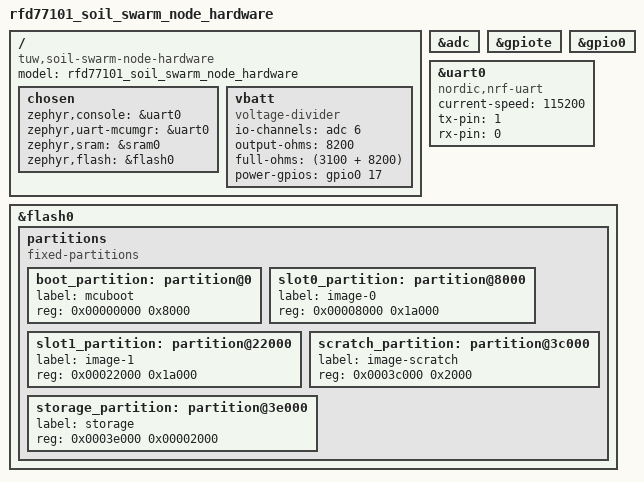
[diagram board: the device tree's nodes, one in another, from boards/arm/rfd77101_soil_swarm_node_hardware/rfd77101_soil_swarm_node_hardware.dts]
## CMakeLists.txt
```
cmake_minimum_required(VERSION 3.8.2)

set(BOARD_ROOT ${CMAKE_CURRENT_LIST_DIR})
set(BOARD rfd77101_soil_swarm_node_hardware)

include($ENV{ZEPHYR_BASE}/cmake/app/boilerplate.cmake NO_POLICY_SCOPE)
project(peripheral)

target_sources(app PRIVATE
  src/main.c
  src/node.c
  src/util.c
  
  src/battery.c
  src/moisture.c
  src/onewire.c
  src/ds18b20.c
  
  src/ass.c
  src/bas.c
  src/cts.c
  src/ess.c
  
  # src/sys_fatal_error_handler.c
)
```

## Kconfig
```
# Copyright (c) 2020 Christian Hirsch
# SPDX-License-Identifier: Apache-2.0

config MEASUREMENTS_SIZE
        int "Number of measurements stored in RAM"
        default 480
        range 0 4094

config SENSE_INTERVAL
        int "Number of measurements stored in RAM"
        default 10
        range 0 4094

source "Kconfig.zephyr"
```

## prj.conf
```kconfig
prj.release.conf
```

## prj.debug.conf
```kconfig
CONFIG_SYSTEM_WORKQUEUE_STACK_SIZE=2048
CONFIG_HEAP_MEM_POOL_SIZE=1024

CONFIG_LOG=y
CONFIG_LOG_BACKEND_UART=y
CONFIG_LOG_DEFAULT_LEVEL=4
CONFIG_LOG_MAX_LEVEL=4

# DEBUGGING
CONFIG_DEBUG=n
CONFIG_BT_DEBUG_LOG=y

# REBOOT
CONFIG_REBOOT=y

# DEVICES
CONFIG_GPIO=y

# BLUETOOTH
CONFIG_BT=y
CONFIG_BT_PERIPHERAL=y
CONFIG_BT_DEVICE_NAME="soil-swarm-node"
CONFIG_BT_CTLR_TX_PWR_PLUS_4=y

CONFIG_ADC=y

CONFIG_PWM=y
```

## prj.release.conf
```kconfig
CONFIG_SYSTEM_WORKQUEUE_STACK_SIZE=2048
CONFIG_HEAP_MEM_POOL_SIZE=1024

# one measurement per 15 min -> 96 / day
CONFIG_SENSE_INTERVAL=900
CONFIG_MEASUREMENTS_SIZE=900

# POWER SAVING
CONFIG_DEBUG=n
CONFIG_SERIAL=n
CONFIG_UART_NRFX=n
CONFIG_BT_DEBUG_LOG=n

# Optimization
CONFIG_SPEED_OPTIMIZATIONS=y

CONFIG_LOG=n
CONFIG_LOG_BACKEND_UART=n

CONFIG_CONSOLE=n
CONFIG_UART_CONSOLE=n

# GENERAL
CONFIG_REBOOT=y

# DEVICES
CONFIG_ADC=y
CONFIG_GPIO=y
CONFIG_PWM=y

# BLUETOOTH
CONFIG_BT=y
CONFIG_BT_PERIPHERAL=y
CONFIG_BT_DEVICE_NAME="soil-swarm-node"
CONFIG_BT_CTLR_TX_PWR_PLUS_4=y

CONFIG_BT_RX_BUF_LEN=130
CONFIG_BT_ATT_TX_MAX=5
CONFIG_BT_ATT_PREPARE_COUNT=2
CONFIG_BT_L2CAP_TX_BUF_COUNT=5
CONFIG_BT_L2CAP_TX_MTU=119
CONFIG_BT_L2CAP_DYNAMIC_CHANNEL=y
CONFIG_BT_CTLR_RX_BUFFERS=2
CONFIG_BT_CTLR_TX_BUFFERS=5
CONFIG_BT_CTLR_TX_BUFFER_SIZE=123
CONFIG_BT_CTLR_DATA_LENGTH_MAX=123
CONFIG_BT_CTLR_ADVANCED_FEATURES=y
CONFIG_BT_CTLR_XTAL_THRESHOLD=500000
```

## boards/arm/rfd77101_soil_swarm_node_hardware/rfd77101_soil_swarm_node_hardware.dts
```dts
/*
 * Copyright (c) 2020 Christian Hirsch
 *
 * SPDX-License-Identifier: Apache-2.0
 */

/dts-v1/;
#include <nordic/nrf51822_qfac.dtsi>

/ {
	model = "rfd77101_soil_swarm_node_hardware";
	compatible = "tuw,soil-swarm-node-hardware";

	chosen {
		zephyr,console = &uart0;
		zephyr,uart-mcumgr = &uart0;
		zephyr,sram = &sram0;
		zephyr,flash = &flash0;
	};
    
	vbatt {
		compatible = "voltage-divider";
		io-channels = <&adc 6>;	/* AIN6 P0.05 */
		output-ohms = <8200>;
		full-ohms = <(3100 + 8200)>;
		power-gpios = <&gpio0 17 0>;
	};
};

&adc {
	status = "okay";
};

&gpiote {
	status = "okay";
};

&gpio0 {
	status = "okay";
};

&uart0 {
		compatible = "nordic,nrf-uart";
        status = "okay";
        current-speed = <115200>;
        tx-pin = <1>;
        rx-pin = <0>;
};

&flash0 {
        /*
         * For more information, see:
         * http://docs.zephyrproject.org/latest/devices/dts/flash_partitions.html
         */
        partitions {
                compatible = "fixed-partitions";
                #address-cells = <1>;
                #size-cells = <1>;

                boot_partition: partition@0 {
                        label = "mcuboot";
                        reg = <0x00000000 0x8000>;
                };
                slot0_partition: partition@8000 {
                        label = "image-0";
                        reg = <0x00008000 0x1a000>;
                };
                slot1_partition: partition@22000 {
                        label = "image-1";
                        reg = <0x00022000 0x1a000>;
                };
                scratch_partition: partition@3c000 {
                        label = "image-scratch";
                        reg = <0x0003c000 0x2000>;
                };
                storage_partition: partition@3e000 {
                        label = "storage";
                        reg = <0x0003e000 0x00002000>;
                };
        };
};
```

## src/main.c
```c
/* main.c - Application main for soil-swarm-node */

#include <zephyr.h>
#include <zephyr/types.h>
#include <sys/byteorder.h>
#include <logging/log.h>
#include <settings/settings.h>
#include <device.h>
#include <drivers/gpio.h>
#include <soc.h>

#include <stddef.h>
#include <string.h>
#include <errno.h>

#include <bluetooth/bluetooth.h>
#include <bluetooth/hci.h>
#include <bluetooth/conn.h>
#include <bluetooth/uuid.h>
#include <bluetooth/gatt.h>

#include "node.h"

#include "config.h"

#define BT_LE_ADV_CONN_NAME_ID BT_LE_ADV_PARAM(BT_LE_ADV_OPT_CONNECTABLE | \
		BT_LE_ADV_OPT_USE_NAME | BT_LE_ADV_OPT_USE_IDENTITY, \
		BT_GAP_ADV_SLOW_INT_MIN, \
		BT_GAP_ADV_SLOW_INT_MAX, NULL)

// BT_GAP_ADV_SLOW_INT_MIN = 0x0640 ^= 1s
// BT_GAP_ADV_SLOW_INT_MAX = 0x0780 ^= 1.2s
#define BT_LE_ADV_NCONN_NAME_ID BT_LE_ADV_PARAM(BT_LE_ADV_OPT_USE_NAME | \
		BT_LE_ADV_OPT_USE_IDENTITY, \
		BT_GAP_ADV_SLOW_INT_MIN, \
		BT_GAP_ADV_SLOW_INT_MAX, NULL)

LOG_MODULE_REGISTER(main);

K_THREAD_STACK_DEFINE(disconnect_timeout_stack, 32);
struct k_thread disconnect_timeout_data;
k_tid_t disconnect_timeout_tid;

void disconnect_timeout(void *, void *, void *);

extern volatile struct time_sync remote_ts;

static bool is_client_connected  = false;
bool is_sync_enabled = false;
struct bt_conn *client_connected = 0;
u32_t time_connected = 0;

struct bt_conn *default_conn;

u16_t num_connected = 0;

struct bt_le_adv_param *adv_params = BT_LE_ADV_CONN_NAME_ID;

static const struct bt_data ad[] = {
		BT_DATA_BYTES(BT_DATA_FLAGS, BT_LE_AD_NO_BREDR),
		BT_DATA_BYTES(BT_DATA_UUID16_ALL, 0xaa, 0xfe),
		BT_DATA_BYTES(BT_DATA_SVC_DATA16,
				0xaa, 0xfe, /* Eddystone UUID */
				0x10, /* Eddystone-URL frame type */
				0x04, /* Calibrated Tx power at 0m */
				0x00, /* URL Scheme Prefix http://www. */
				//'a','f','a','r','c','l','o','u','d','.','e','u','/')
				'a','f','a','r','c','l','o','u','d','.','a','t','/')
};

void start_advertising() {
	bt_le_adv_start(BT_LE_ADV_CONN_NAME_ID, ad, ARRAY_SIZE(ad), NULL, 0);
	return;
	int err = 0, err_cnt = 0;
	do {
		err = bt_le_adv_start(adv_params, ad, ARRAY_SIZE(ad), NULL, 0);
		if(err == 0 || err_cnt > 3)
			break;
		err_cnt++;
		k_sleep(K_MSEC(15));
	} while(err);

	if (err) {
		LOG_ERR("Advertising failed to start (err %d)", err);
		return;
	}
	LOG_INF("Advertising successfully started");
}

static void connected(struct bt_conn *conn, u8_t err)
{
	if (err) {
		LOG_INF("Connection failed (err %u)\n", err);
		return;
	}

	client_connected = conn;
	is_client_connected = true;

	disconnect_timeout_tid = k_thread_create(&disconnect_timeout_data,
			disconnect_timeout_stack,
			K_THREAD_STACK_SIZEOF(disconnect_timeout_stack),
			disconnect_timeout,
			NULL, NULL, NULL, 1, 0, K_SECONDS(300));
	num_connected++;

	LOG_INF("Connected (%u times)", num_connected);
}

static void disconnected(struct bt_conn *conn, u8_t reason)
{
	LOG_INF("Disconnected (reason %u)\n", reason);
	is_client_connected = false;

	if (disconnect_timeout_tid)
	{
		k_wakeup(disconnect_timeout_tid);
	}
}

static void bt_ready(int err)
{
	if (err) {
		LOG_ERR("Bluetooth init failed (err %d)", err);
		return;
	}
	LOG_INF("Bluetooth initialized");

	if (IS_ENABLED(CONFIG_SETTINGS)) {
		settings_load();
	}

	start_advertising();
}

static struct bt_conn_cb conn_callbacks = {
	.connected = connected,
	.disconnected = disconnected,
};

void disconnect_timeout(void *v1, void *v2, void *v3)
{
	/* if connection is still up after 15min, (auto-)disconnect */
	if (is_client_connected == true)
	{
		bt_conn_disconnect(client_connected, BT_HCI_ERR_REMOTE_USER_TERM_CONN);
	}

	disconnect_timeout_tid = 0;
}

void main(void)
{
	int err = 0;

	err = bt_enable(bt_ready);
	if (err != 0) {
		LOG_ERR("Bluetooth init failed (err %d)", err);
		return;
	}
	bt_conn_cb_register(&conn_callbacks);

	while (1) {
		k_sleep(K_FOREVER);
	}
}
```

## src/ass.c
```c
#include "ass.h"

#include "uuid.h"
#include "node.h"

#include <logging/log.h>

#include <bluetooth/gatt.h>
#include <bluetooth/conn.h>

static u8_t *data_buf = NULL;

static u8_t indicate_enabled = 0;
static u16_t mtu_size = 0;

static size_t buffer_size = 0;
static size_t mtu_buffer_size = 0;

struct bt_gatt_indicate_params i_params;

extern struct bt_conn *client_connected;

LOG_MODULE_REGISTER(ASS);

static void sync_ccc_cfg_changed(const struct bt_gatt_attr *attr,
			u16_t value);
static void ass_indicate(void);

/* ASS Declaration */
BT_GATT_SERVICE_DEFINE(ass_svc,
	BT_GATT_PRIMARY_SERVICE(BT_UUID_ASS),

	BT_GATT_CHARACTERISTIC(BT_UUID_ASS_GSC,
			       BT_GATT_CHRC_READ | BT_GATT_CHRC_INDICATE,
			       BT_GATT_PERM_READ, NULL, NULL, NULL),

	BT_GATT_CCC(sync_ccc_cfg_changed, BT_GATT_PERM_READ | BT_GATT_PERM_WRITE),

	BT_GATT_DESCRIPTOR(BT_UUID_ASS_UTD, BT_GATT_PERM_NONE, NULL, NULL, 0),
	BT_GATT_DESCRIPTOR(BT_UUID_ASS_BVD, BT_GATT_PERM_NONE, NULL, NULL, 0),
	BT_GATT_DESCRIPTOR(BT_UUID_ASS_STD, BT_GATT_PERM_NONE, NULL, NULL, 0),
	BT_GATT_DESCRIPTOR(BT_UUID_ASS_RSHD, BT_GATT_PERM_NONE, NULL, NULL, 0),
);

static void indicate_cb(struct bt_conn *conn, const struct bt_gatt_attr *attr,
			u8_t err)
{
	LOG_INF("Indication %s\n", err != 0U ? "fail" : "success");
	node_buf_get_finish(mtu_buffer_size);
	ass_indicate();
}

static void sync_ccc_cfg_changed(const struct bt_gatt_attr *attr,
				 u16_t value)
{
	indicate_enabled = (value == BT_GATT_CCC_INDICATE) ? 1 : 0;

	LOG_INF("sync_ccc_cfg_changed to %u", value);

	if (indicate_enabled)
	{
		mtu_size = bt_gatt_get_mtu(client_connected);
		LOG_INF("mtu size = %u", mtu_size);

		data_buf = (u8_t *)k_malloc(mtu_size);

		if(data_buf == 0)
		{
			LOG_ERR("error allocating %u bytes of memory", mtu_size);
			return;
		}

		i_params.attr = &ass_svc.attrs[2];
		i_params.data = data_buf;
		i_params.func = indicate_cb;

		buffer_size = node_buf_get_elem_size();
		mtu_buffer_size = (mtu_size - 4) / buffer_size;

		ass_indicate();
	}
	else {
		k_free(data_buf);
		data_buf = 0;
	}
}

static void ass_indicate(void)
{
	if(!indicate_enabled)
		return;

	LOG_INF("send indication");

	data_buf[0] = (u8_t) node_buf_cpy_data((void *)&data_buf[1],
			mtu_buffer_size);

	i_params.len  = sizeof(data_buf[0]) + data_buf[0] * buffer_size;
	if (data_buf[0] == 0) {
		i_params.func = NULL;
	}

	int err = bt_gatt_indicate(NULL, &i_params);
	if (err != 0) {
		LOG_ERR("error sending indication: %i", err);
	}
}
```

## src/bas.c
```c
#include <zephyr.h>
#include <zephyr/types.h>

#include <bluetooth/bluetooth.h>
#include <bluetooth/conn.h>
#include <bluetooth/uuid.h>
#include <bluetooth/gatt.h>

#include "battery.h"

static ssize_t read_blvl(struct bt_conn *conn, const struct bt_gatt_attr *attr,
		void *buf, u16_t len, u16_t offset)
{
	u16_t value = (u16_t) battery_sample();// battery_level_pptt(battery_sample());

	return bt_gatt_attr_read(conn, attr, buf, len, offset, &value,
			sizeof(value));
}

/* Battery Service Declaration */
BT_GATT_SERVICE_DEFINE(bas_svc,
	BT_GATT_PRIMARY_SERVICE(BT_UUID_BAS),
	BT_GATT_CHARACTERISTIC(BT_UUID_BAS_BATTERY_LEVEL,
			BT_GATT_CHRC_READ | BT_GATT_CHRC_NOTIFY,
			BT_GATT_PERM_READ, read_blvl, NULL, NULL),
	BT_GATT_CCC(NULL, BT_GATT_PERM_NONE)
);
```

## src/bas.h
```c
/** @file
 *  @brief BAS Service sample
 */

/*
 * Copyright (c) 2016 Intel Corporation
 *
 * SPDX-License-Identifier: Apache-2.0
 */

#ifdef __cplusplus
extern "C" {
#endif

int  bas_notify(u16_t _battery_lvl);

#ifdef __cplusplus
}
#endif
```

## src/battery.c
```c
//#include "battery.h"

//#include "settings.h"
#include <device.h>
#include <drivers/gpio.h>

#include <drivers/adc.h>
#include <hal/nrf_adc.h>

#define BATTERY_EN_PIN 17

struct device *battery_en;

#define BUFFER_SIZE 1
static int32_t m_sample_buffer[BUFFER_SIZE];

struct device *adc_dev;

static const struct adc_channel_cfg adc_cfg = {
    .gain             = ADC_GAIN_1_3,
    .reference        = ADC_REF_VDD_1_3,
    .acquisition_time = ADC_ACQ_TIME_DEFAULT,
//    .channel_id       = ADC_1ST_CHANNEL_ID,
//    .channel_id       = BATTERY_SENSE_PIN,
    .input_positive   = NRF_ADC_CONFIG_INPUT_6,
};

struct adc_sequence adc_sequence = {
//    .channels    = BIT(ADC_1ST_CHANNEL_ID),
    .buffer      = m_sample_buffer,
    .buffer_size = sizeof(m_sample_buffer),
    .resolution  = 10,
};

int battery_init(struct device *a_dev) {
    battery_en = device_get_binding(DT_LABEL(DT_ALIAS(gpio_0)));

    gpio_pin_configure(battery_en, BATTERY_EN_PIN, GPIO_OUTPUT);
    gpio_pin_set(battery_en, BATTERY_EN_PIN, 0);

	adc_dev = device_get_binding(DT_LABEL(DT_ALIAS(adc_0)));

    if(adc_dev == 0)
        return -1;

    return adc_channel_setup(adc_dev, &adc_cfg);
}

int16_t battery_sample() {
	int err = 0;

    if(adc_channel_setup(adc_dev, &adc_cfg) != 0)
        return -1;
    adc_sequence.channels = BIT(adc_cfg.channel_id);

    gpio_pin_set(battery_en, BATTERY_EN_PIN, 1);
    err = adc_read(adc_dev, &adc_sequence);
    gpio_pin_set(battery_en, BATTERY_EN_PIN, 0);

    err = adc_raw_to_millivolts(1000, adc_cfg.gain, adc_sequence.resolution, &m_sample_buffer[0]);
    if (err == 0) {
    	m_sample_buffer[0] *= (82+31);
    	m_sample_buffer[0] /= (82);
    }

    if(err < 0)
        return -EIO;

    return m_sample_buffer[0];
}
```

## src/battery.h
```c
/*
 * Copyright (c) 2018-2019 Peter Bigot Consulting, LLC
 *
 * SPDX-License-Identifier: Apache-2.0
 */

#ifndef APPLICATION_BATTERY_H_
#define APPLICATION_BATTERY_H_

/** Enable or disable measurement of the battery voltage.
 *
 * @param enable true to enable, false to disable
 *
 * @return zero on success, or a negative error code.
 */
int battery_measure_enable(bool enable);

/** Measure the battery voltage.
 *
 * @return the battery voltage in millivolts, or a negative error
 * code.
 */
s16_t battery_sample(void);

/** A point in a battery discharge curve sequence.
 *
 * A discharge curve is defined as a sequence of these points, where
 * the first point has #lvl_pptt set to 10000 and the last point has
 * #lvl_pptt set to zero.  Both #lvl_pptt and #lvl_mV should be
 * monotonic decreasing within the sequence.
 */
struct battery_level_point {
	/** Remaining life at #lvl_mV. */
	u16_t lvl_pptt;

	/** Battery voltage at #lvl_pptt remaining life. */
	u16_t lvl_mV;
};

/** Calculate the estimated battery level based on a measured voltage.
 *
 * @param batt_mV a measured battery voltage level.
 *
 * @param curve the discharge curve for the type of battery installed
 * on the system.
 *
 * @return the estimated remaining capacity in parts per ten
 * thousand.
 */
u16_t battery_level_pptt(unsigned int batt_mV);

void battery_charge_enable(void);
void battery_charge_disable(void);
u8_t battery_charge_is_enabled(void);

#endif /* APPLICATION_BATTERY_H_ */
```

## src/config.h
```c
#define SENSE_INTERVAL CONFIG_SENSE_INTERVAL
#define MEASUREMENTS_SIZE CONFIG_MEASUREMENTS_SIZE

#define LED_PORT "GPIO_0"
#define LED_P    6
#define LED_N    4

#define BATTERY_EN_PORT "GPIO_0"
#define BATTERY_EN_PIN  17

#define ONEWIRE_PORT "GPIO_0"
#define ONEWIRE_PIN  14

#define DS18B20_EN_PORT "GPIO_0"
#define DS18B20_EN_PIN  13

#define SENSE_EN_PORT "GPIO_0"
#define SENSE_EN_PIN  7

#define SENSE_EXCITATION_PORT "GPIO_0"
#define SENSE_EXCITATION_PIN  10

#define SENSE_LOW_PIN   NRF_ADC_CONFIG_INPUT_3   //P0.02/AIN3
#define SENSE_HIGH_PIN  NRF_ADC_CONFIG_INPUT_4   //P0.03/AIN4

#define ADC_RESOLUTION          10
#define ADC_GAIN                ADC_GAIN_1_3
#define ADC_REFERENCE           ADC_REF_INTERNAL
#define ADC_ACQUISITION_TIME    ADC_ACQ_TIME_DEFAULT
#define BATTERY_SENSE_PIN       ADC_CONFIG_PSEL_AnalogInput6  // P0.05/GPIO5/ANALOG6
```

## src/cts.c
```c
#include <zephyr.h>
#include <zephyr/types.h>
#include <stddef.h>
#include <string.h>
#include <time.h>
#include <errno.h>

#include <sys/byteorder.h>

#include <bluetooth/bluetooth.h>
#include <bluetooth/hci.h>
#include <bluetooth/conn.h>
#include <bluetooth/uuid.h>
#include <bluetooth/gatt.h>

#include "cts.h"
#include "node.h"
#include "config.h"

#include <drivers/counter.h>

static  u8_t cts_exact_time_256[10];
static  u8_t cts_update;

s64_t cts_uptime_synced_ms = 0;
u32_t cts_uptime_synced_s  = 0;
u32_t cts_ref_unix_sec     = 0;

static u8_t counting = 0;

static ssize_t read_cts(struct bt_conn *conn, const struct bt_gatt_attr *attr,
		void *buf, u16_t len, u16_t offset);
static ssize_t write_cts(struct bt_conn *conn, const struct bt_gatt_attr *attr,
		const void *buf, u16_t len, u16_t offset,
		u8_t flags);

/* Battery Service Declaration */
BT_GATT_SERVICE_DEFINE(cts_svc,
		BT_GATT_PRIMARY_SERVICE(BT_UUID_CTS),
		BT_GATT_CHARACTERISTIC(BT_UUID_CTS_CURRENT_TIME,
				BT_GATT_CHRC_READ | BT_GATT_CHRC_WRITE,
				BT_GATT_PERM_READ | BT_GATT_PERM_WRITE,
				read_cts, write_cts, cts_exact_time_256),
				BT_GATT_CCC(NULL, BT_GATT_PERM_NONE),
);

/* no leap seconds! */
static u32_t exact_time_256_to_unix_sec(u8_t *ct)
{
	u32_t year = (u32_t)sys_le16_to_cpu(*(u16_t *)ct);

	u32_t time_sec = (year - 1) / 4;
	time_sec   = (time_sec - 492) * 24 * 60 * 60;		// leap year days
	time_sec  += (year - 1970) * 365 * 24 * 60 * 60;	//without leap year

	for(u8_t i=1; i<ct[2]; i++)
	{
		switch(i) {
		case 2:
			time_sec += 28 * 24 * 60 * 60;
			if(year % 4 == 0)
			{
				time_sec += 24 * 60 * 60;
			}
			break;
		case 4:
		case 6:
		case 9:
		case 11:
			time_sec += 30 * 24 * 60 * 60;
			break;
		default:
			time_sec += 31 * 24 * 60 * 60;
			break;
		}
	}

	time_sec += (ct[3]-1) * 24 * 60 * 60;	// day of month
	time_sec += (ct[4]) * 60 * 60;			// hours
	time_sec += (ct[5]) * 60;				// minutes
	time_sec += (ct[6]);					// seconds

	return time_sec;
}

static void unix_sec_to_exact_time_256(u32_t unix_sec, u8_t *et256)
{
	u32_t tmp = 0;

	/* seconds */
	et256[6] =  unix_sec % 60;

	/* minutes */
	et256[5] = (unix_sec / 60) % 60;

	/* hours */
	et256[4] = (unix_sec / 3600) % 24;

	/* year */
	tmp  = (unix_sec / 3600 / 24) * 100;
	tmp /= 36525;
	tmp += 1970;
	memcpy(&et256[0], &tmp, sizeof(tmp));

	/* day of month */
	tmp  = (u32_t) *(u16_t *)et256 - 1970;
	tmp *= 36525;
	tmp += 50;
	tmp /= 100;
	tmp  = (unix_sec / 3600 / 24) - tmp + 1;

	for(et256[2] = 1; et256[2] < 13 ; et256[2]++)
	{
		u8_t days;
		switch(et256[2])
		{
		case 2:
			days = 28;
			break;
		case 4:
		case 6:
		case 9:
		case 11:
			days = 30;
			break;
		default:
			days = 31;
			break;
		}
		if (tmp < days)
			break;
		tmp -= days;
	}

	et256[3] = (u8_t) tmp;
	if (et256[2] < 3 && (*(u16_t *)et256 - 1970) % 4 == 2) {
		et256[3]++;
	}
}

static ssize_t read_cts(struct bt_conn *conn, const struct bt_gatt_attr *attr,
		void *buf, u16_t len, u16_t offset)
{
	u8_t et256[10] = { 0 };

	s64_t now  = (k_uptime_get() - cts_uptime_synced_ms) / 1000;

	u32_t now32 = (u32_t) now;
	now32 += cts_ref_unix_sec;

	unix_sec_to_exact_time_256(now32, et256);

	int err = bt_gatt_attr_read(conn, attr, buf, len, offset, et256,
			sizeof(et256));

	return err;
}

static ssize_t write_cts(struct bt_conn *conn, const struct bt_gatt_attr *attr,
		const void *buf, u16_t len, u16_t offset,
		u8_t flags)
{
	s64_t now = k_uptime_get();

	u8_t *value = attr->user_data;

	if (offset + len > sizeof(cts_exact_time_256)) {
		return BT_GATT_ERR(BT_ATT_ERR_INVALID_OFFSET);
	}

	memcpy(value + offset, buf, len);

	cts_update = 1U;
	cts_uptime_synced_ms = now;
	now /= 1000;
	cts_uptime_synced_s = (u32_t) now;
	cts_ref_unix_sec = exact_time_256_to_unix_sec(cts_exact_time_256);

	if (counting == 1) {
		// clock stretching?!

	}

	now  = cts_ref_unix_sec % (SENSE_INTERVAL);
	now  = 1000 * now + (cts_uptime_synced_ms % 1000);

	node_start_sensing(SENSE_INTERVAL - now);
	counting = 1;

	return len;
}
```

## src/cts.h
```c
/** @file
 *  @brief BAS Service sample
 */

/*
 * Copyright (c) 2016 Intel Corporation
 *
 * SPDX-License-Identifier: Apache-2.0
 */

#ifdef __cplusplus
extern "C" {
#endif

volatile struct time_sync {
	u32_t remote_time;
	u8_t  is_remotely_synced;
	u32_t time_synced;
};

void cts_init(void);
int  cts_notify(u32_t _timestamp);

#ifdef __cplusplus
}
#endif
```

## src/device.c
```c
#include <zephyr.h>
#include <power.h>
#include <soc_power.h>
#include <misc/printk.h>
#include <string.h>
#include <soc.h>
#include <device.h>

static struct device *gpiob;
static struct device *device_list;
static int device_count;

/*
 * Example ordered list to store devices on which
 * device power policies would be executed.
 */
#define DEVICE_POLICY_MAX 15
static char device_ordered_list[DEVICE_POLICY_MAX];
static char device_retval[DEVICE_POLICY_MAX];

void suspend_devices(void)
{
    /*  * /
    for (int i = device_count - 1; i >= 0; i--) {
        int idx = device_ordered_list[i];

        / * If necessary  the policy manager can check if a specific
         * device in the device list is busy as shown below :
         * if(device_busy_check(&device_list[idx])) {do something}
         * /
        device_retval[i] = device_set_power_state(&device_list[idx],
                        DEVICE_PM_SUSPEND_STATE);
    }
    /*  */
}

void resume_devices(void)
{
    /*  * /
    int i;

    for (i = 0; i < device_count; i++) {
        if (!device_retval[i]) {
            int idx = device_ordered_list[i];

            device_set_power_state(&device_list[idx],
                        DEVICE_PM_ACTIVE_STATE);
        }
    }
    / *  */
}

void create_device_list(void)
{
    int count;
    int i;

    /*
     * Following is an example of how the device list can be used
     * to suspend devices based on custom policies.
     *
     * Create an ordered list of devices that will be suspended.
     * Ordering should be done based on dependencies. Devices
     * in the beginning of the list will be resumed first.
     */
    device_list_get(&device_list, &count);
    device_count = 4; /* Reserve for 32KHz, 16MHz, system clock, and uart */

    for (i = 0; (i < count) && (device_count < DEVICE_POLICY_MAX); i++) {
        if (!strcmp(device_list[i].config->name, "clk_k32src")) {
            device_ordered_list[0] = i;
        } else if (!strcmp(device_list[i].config->name, "clk_m16src")) {
            device_ordered_list[1] = i;
        } else if (!strcmp(device_list[i].config->name, "sys_clock")) {
            device_ordered_list[2] = i;
        } else if (!strcmp(device_list[i].config->name, "UART_0")) {
            device_ordered_list[3] = i;
        } else {
            device_ordered_list[device_count++] = i;
        }
    }
}
```

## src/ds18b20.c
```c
#include "ds18b20.h"
#include "onewire.h"

#include "config.h"

#include <zephyr.h>
#include <device.h>
#include <drivers/gpio.h>

struct device *ds18b20_dev;

K_SEM_DEFINE(ds18b20_guard, 1, 1);

s8_t ds18b20_init(void) {
    ds18b20_dev = device_get_binding(DS18B20_EN_PORT);
    if(ds18b20_dev == NULL)
        return -1;

    s8_t ret = gpio_pin_configure(ds18b20_dev, DS18B20_EN_PIN, GPIO_OUTPUT);
    if(ret != 0)
        return ret;

    SetSpeed(1);
	
    ds18b20_disable();

    return 0;
}

int ds18b20_enable(k_timeout_t timeout)
{
	int err = k_sem_take(&ds18b20_guard, timeout);
	if (err != 0)
		return err;

    OWPower();

    return gpio_pin_set(ds18b20_dev, DS18B20_EN_PIN, 1);
}

int ds18b20_disable(void)
{
	OWDepower();

	int ret = gpio_pin_set(ds18b20_dev, DS18B20_EN_PIN, 0);

    k_sem_give(&ds18b20_guard);

    if (ret != 0) {
        return ret;
    }

	return 0;
}

s16_t ds18b20_measure_temp(void)
{
    if(OWTouchReset())
        return -1000;

    OWWriteByte(0xCC, 0);  // Send Skip ROM command to select single device
    OWWriteByte(0x44, 1);  // start conversion, parasite power on

	return 0;
}

s16_t ds18b20_read_temp(void)
{
	u8_t data[9];

    if(OWTouchReset())
        return -1000;

    OWWriteByte(0xCC, 0);  // Send Skip ROM command to select single device
    OWWriteByte(0xBE, 0);  // read 9 bytes of scratchpad

    for (u8_t i=0; i<9; i++)
    {
        data[i] = OWReadByte();
    }

	OWTouchReset();

    return ((data[1] & 0xff) << 8) | (data[0] & 0xff);
}
```

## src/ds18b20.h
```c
#include <zephyr.h>

s8_t  ds18b20_init(void);
int   ds18b20_enable(k_timeout_t timeout);
int   ds18b20_disable(void);
s16_t ds18b20_measure_temp(void);
s16_t ds18b20_read_temp(void);
```

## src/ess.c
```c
/** @file
 *  @brief BAS Service sample
 */

/*
 * Copyright (c) 2016 Intel Corporation
 *
 * SPDX-License-Identifier: Apache-2.0
 */

#include <zephyr.h>
#include <zephyr/types.h>
#include <stddef.h>
#include <string.h>
#include <errno.h>
#include <sys/byteorder.h>

#include <bluetooth/bluetooth.h>
#include <bluetooth/hci.h>
#include <bluetooth/conn.h>
#include <bluetooth/uuid.h>
#include <bluetooth/gatt.h>

#include "ds18b20.h"
#include "moisture.h"
#include "util.h"

static ssize_t read_temp(struct bt_conn *conn, const struct bt_gatt_attr *attr,
        void *buf, u16_t len, u16_t offset);
static ssize_t read_humi(struct bt_conn *conn, const struct bt_gatt_attr *attr,
			 void *buf, u16_t len, u16_t offset);

/* ESS Declaration */
BT_GATT_SERVICE_DEFINE(ess_svc,
	BT_GATT_PRIMARY_SERVICE(BT_UUID_ESS),
	BT_GATT_CHARACTERISTIC(BT_UUID_TEMPERATURE,
			       BT_GATT_CHRC_READ | BT_GATT_CHRC_NOTIFY,
			       BT_GATT_PERM_READ, read_temp, NULL, NULL),
	BT_GATT_CCC(NULL, BT_GATT_PERM_NONE),
	BT_GATT_CHARACTERISTIC(BT_UUID_HUMIDITY,
			       BT_GATT_CHRC_READ | BT_GATT_CHRC_NOTIFY,
			       BT_GATT_PERM_READ, read_humi, NULL, NULL),
	BT_GATT_CCC(NULL, BT_GATT_PERM_NONE),
);

static ssize_t read_temp(struct bt_conn *conn, const struct bt_gatt_attr *attr,
        void *buf, u16_t len, u16_t offset)
{
    ds18b20_enable(K_FOREVER);
    k_sleep(K_MSEC(1));
    s16_t temperature = ds18b20_measure_temp();
    if (temperature == 0) {
    	k_sleep(K_MSEC(750));
        temperature = ds18b20_read_temp();
	}
    else {
        temperature = -1001;
    }
    ds18b20_disable();

    temperature = util_temperature_to_ble(temperature);

    return bt_gatt_attr_read(conn, attr, buf, len, offset, &temperature,
            sizeof(temperature));
}

static ssize_t read_humi(struct bt_conn *conn, const struct bt_gatt_attr *attr,
			 void *buf, u16_t len, u16_t offset)
{
    u16_t humidity = util_humidity_to_ble(moisture_read_value());

	return bt_gatt_attr_read(conn, attr, buf, len, offset, &humidity,
				 sizeof(humidity));
}
```
